# GD32W515 register map
File version: 1.0
CPU: CM33 r0p4, little endian, MPU, FPU, 4 interrupt priority bits
Registers are 32-bit, read-write, reset 0x0 unless marked. A register's access mark holds for its fields unless they carry their own. Offsets are from the block's base; [hi:lo] are bit positions.

## SPI0 — Serial peripheral interface
Base 0x40013000
Same registers: SEC_SPI0 0x50013000
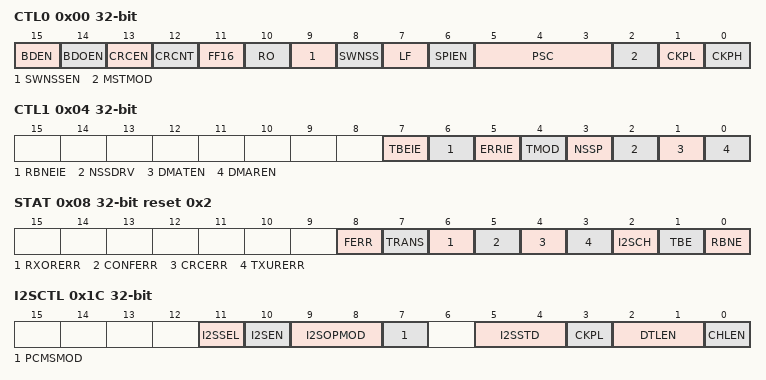
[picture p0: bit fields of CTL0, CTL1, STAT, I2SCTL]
0x00 CTL0 — control register 0
  [15] BDEN — Bidirectional enable
  [14] BDOEN — Bidirectional Transmit output enable
  [13] CRCEN — CRC Calculation Enable
  [12] CRCNT — CRC Next Transfer
  [11] FF16 — Data frame format
  [10] RO — Receive only
  [9] SWNSSEN — NSS Software Mode Selection
  [8] SWNSS — NSS Pin Selection In NSS Software Mode
  [7] LF — LSB First Mode
  [6] SPIEN — SPI enable
  [5:3] PSC — Master Clock Prescaler Selection
  [2] MSTMOD — Master Mode Enable
  [1] CKPL — Clock polarity Selection
  [0] CKPH — Clock Phase Selection
0x04 CTL1 — control register 1
  [7] TBEIE — Tx buffer empty interrupt enable
  [6] RBNEIE — RX buffer not empty interrupt enable
  [5] ERRIE — Error interrupt enable
  [4] TMOD — SPI TI Mode Enable
  [3] NSSP — SPI NSS pulse mode Enable
  [2] NSSDRV — Drive NSS Output
  [1] DMATEN — Transmit Buffer DMA Enable
  [0] DMAREN — Rx buffer DMA enable
0x08 STAT access per field reset 0x2 — status register
  [8] FERR rw — Format Error
  [7] TRANS ro — Transmitting On-going Bit
  [6] RXORERR ro — Reception Overrun Error Bit
  [5] CONFERR ro — SPI Configuration error
  [4] CRCERR rw — SPI CRC Error Bit
  [3] TXURERR ro — Transmission underrun error bit
  [2] I2SCH ro — I2S channel side
  [1] TBE ro — Transmit Buffer Empty
  [0] RBNE ro — Receive Buffer Not Empty
0x0C DATA
  [15:0] SPI_DATA — Data transfer register
0x10 CRCPOLY reset 0x7 — CRC polynomial register
  [15:0] CRCPOLY
0x14 RCRC ro — RX CRC register
  [15:0] RCRC
0x18 TCRC ro — TX CRC register
  [15:0] TCRC — Tx CRC register
0x1C I2SCTL — I2S control register
  [11] I2SSEL — I2S mode selection
  [10] I2SEN — I2S Enable
  [9:8] I2SOPMOD — I2S operation mode
  [7] PCMSMOD — PCM frame synchronization mode
  [5:4] I2SSTD — I2S standard selection
  [3] CKPL — Idle state clock polarity
  [2:1] DTLEN — Data length
  [0] CHLEN — Channel length (number of bits per audio channel)
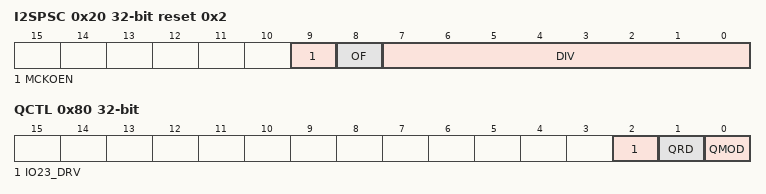
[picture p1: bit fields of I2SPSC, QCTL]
0x20 I2SPSC reset 0x2 — I2S prescaler register
  [9] MCKOEN — I2S_MCK output enable
  [8] OF — Odd factor for the prescaler
  [7:0] DIV — Dividing factor for the prescaler
0x80 QCTL — Quad-SPI mode control register
  [2] IO23_DRV — Drive IO2 and IO3 enable
  [1] QRD — Quad-SPI mode read select
  [0] QMOD — Quad-SPI mode enable

## SPI1 — Serial peripheral interface
Base 0x40003800
Same registers: I2S1_add 0x40003400, SEC_I2S1_add 0x50003400, SEC_SPI1 0x50003800
Registers as SPI0, without QCTL.

## SQPI — Serial/Quad Parallel Interface
Base 0x40025400
Same registers: SEC_SQPI 0x50025400
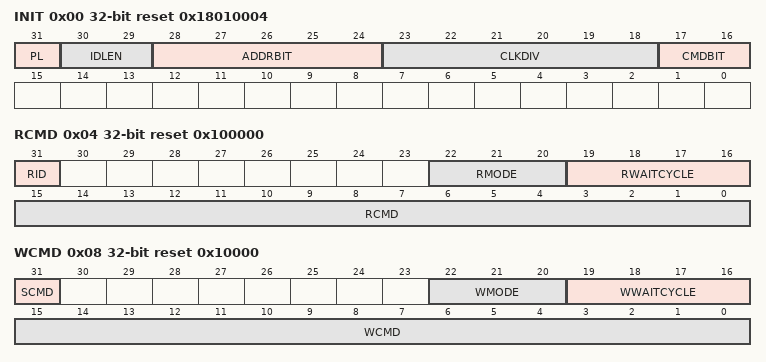
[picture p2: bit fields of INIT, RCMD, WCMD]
0x00 INIT reset 0x18010004 — SQPI Initial Register
  [31] PL — Read data sample polarity.
  [30:29] IDLEN — SQPI controller external memory ID length
  [28:24] ADDRBIT — Bit number of SPI PSRAM address phase.
  [23:18] CLKDIV — Clock divider for SQPI output clock
  [17:16] CMDBIT — Bit number of SQPI controller command phase
0x04 RCMD reset 0x100000 — SQPI Read Command Register
  [31] RID — Send read ID command
  [22:20] RMODE — SQPI controller read command mode
  [19:16] RWAITCYCLE — SQPI read command waitcycle number after address phase
  [15:0] RCMD — SQPI read command for AHB read transfer
0x08 WCMD reset 0x10000 — Write Command Register
  [31] SCMD — Send special command
  [22:20] WMODE — SQPI controller write command mode
  [19:16] WWAITCYCLE — SQPI write command waitcycle number after address phase
  [15:0] WCMD — SQPI write command for AHB write transfer
0x0C IDL ro — ID Low Register
  [31:0] IDL — ID Low Data saved for SQPI Read ID Command
0x10 IDH ro — ID High Register
  [31:0] IDH — ID High Data saved for SQPI read ID command
